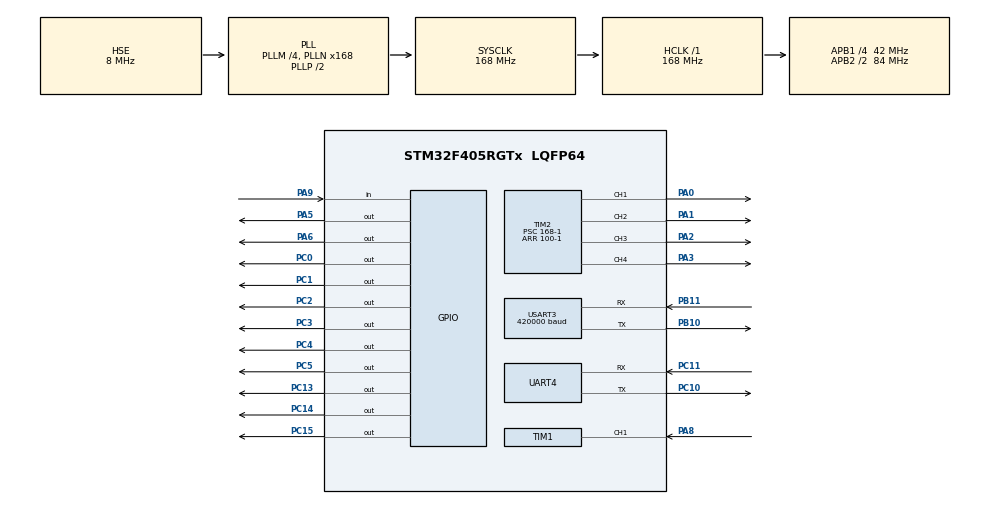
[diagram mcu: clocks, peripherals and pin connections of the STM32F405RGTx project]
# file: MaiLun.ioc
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Mcu.Family=STM32F4
Mcu.Name=STM32F405RGTx
Mcu.Package=LQFP64
NVIC.PriorityGroup=NVIC_PRIORITYGROUP_4
NVIC.TIM1_CC_IRQn=true\:1\:0\:true\:false\:true\:true\:true\:true
NVIC.TIM3_IRQn=true\:2\:0\:true\:false\:true\:true\:true\:true
NVIC.UART4_IRQn=true\:2\:0\:true\:false\:true\:true\:true\:true
NVIC.USART3_IRQn=true\:1\:0\:true\:false\:true\:true\:true\:true
PA0-WKUP.Signal=S_TIM2_CH1_ETR
PA1.Signal=S_TIM2_CH2
PA13.Mode=Serial_Wire
PA13.Signal=SYS_JTMS-SWDIO
PA14.Mode=Serial_Wire
PA14.Signal=SYS_JTCK-SWCLK
PA2.Signal=S_TIM2_CH3
PA3.Signal=S_TIM2_CH4
PA5.Signal=GPIO_Output
PA6.Signal=GPIO_Output
PA8.Signal=S_TIM1_CH1
PA9.Signal=GPIO_Input
PB10.Mode=Asynchronous
PB10.Signal=USART3_TX
PB11.Mode=Asynchronous
PB11.Signal=USART3_RX
PC0.Signal=GPIO_Output
PC1.Signal=GPIO_Output
PC10.Mode=Asynchronous
PC10.Signal=UART4_TX
PC11.Mode=Asynchronous
PC11.Signal=UART4_RX
PC13-ANTI_TAMP.Signal=GPIO_Output
PC14-OSC32_IN.Signal=GPIO_Output
PC15-OSC32_OUT.Signal=GPIO_Output
PC2.Signal=GPIO_Output
PC3.Signal=GPIO_Output
PC4.Signal=GPIO_Output
PC5.Signal=GPIO_Output
PH0-OSC_IN.Mode=HSE-External-Oscillator
PH0-OSC_IN.Signal=RCC_OSC_IN
PH1-OSC_OUT.Mode=HSE-External-Oscillator
PH1-OSC_OUT.Signal=RCC_OSC_OUT
ProjectManager.HeapSize=0x200
ProjectManager.StackSize=0x400
ProjectManager.TargetToolchain=CMake
RCC.48MHZClocksFreq_Value=84000000
RCC.AHBFreq_Value=168000000
RCC.APB1CLKDivider=RCC_HCLK_DIV4
RCC.APB1Freq_Value=42000000
RCC.APB1TimFreq_Value=84000000
RCC.APB2CLKDivider=RCC_HCLK_DIV2
RCC.APB2Freq_Value=84000000
RCC.APB2TimFreq_Value=168000000
RCC.CortexFreq_Value=168000000
RCC.HCLKFreq_Value=168000000
RCC.HSE_VALUE=8000000
RCC.HSI_VALUE=16000000
RCC.LSE_VALUE=32768
RCC.PLLM=4
RCC.PLLN=168
RCC.PLLSourceVirtual=RCC_PLLSOURCE_HSE
RCC.SYSCLKFreq_VALUE=168000000
RCC.SYSCLKSource=RCC_SYSCLKSOURCE_PLLCLK
RCC.VCOOutputFreq_Value=336000000
SH.S_TIM1_CH1.0=TIM1_CH1,Input_Capture1_from_TI1
SH.S_TIM2_CH1_ETR.0=TIM2_CH1,PWM Generation1 CH1
SH.S_TIM2_CH2.0=TIM2_CH2,PWM Generation2 CH2
SH.S_TIM2_CH3.0=TIM2_CH3,PWM Generation3 CH3
SH.S_TIM2_CH4.0=TIM2_CH4,PWM Generation4 CH4
TIM1.Channel-Input_Capture1_from_TI1=TIM_CHANNEL_1
TIM1.Prescaler=8400-1
TIM2.AutoReloadPreload=TIM_AUTORELOAD_PRELOAD_ENABLE
TIM2.Channel-PWM\ Generation1\ CH1=TIM_CHANNEL_1
TIM2.Channel-PWM\ Generation2\ CH2=TIM_CHANNEL_2
TIM2.Channel-PWM\ Generation3\ CH3=TIM_CHANNEL_3
TIM2.Channel-PWM\ Generation4\ CH4=TIM_CHANNEL_4
TIM2.Period=100-1
TIM2.Prescaler=168-1
TIM3.Period=1000-1
TIM3.Prescaler=8400-1
UART4.VirtualMode=Asynchronous
USART3.BaudRate=420000
USART3.VirtualMode=VM_ASYNC
VP_TIM1_VS_ClockSourceINT.Mode=Internal
VP_TIM2_VS_ClockSourceINT.Mode=Internal
VP_TIM3_VS_ClockSourceINT.Mode=Internal
board=custom

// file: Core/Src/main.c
/* USER CODE BEGIN Header */
/**
  ******************************************************************************
  * @file           : main.c
  * @brief          : Main program body
  ******************************************************************************
  * @attention
  *
  * Copyright (c) 2026 STMicroelectronics.
  * All rights reserved.
  *
  * This software is licensed under terms that can be found in the LICENSE file
  * in the root directory of this software component.
  * If no LICENSE file comes with this software, it is provided AS-IS.
  *
  ******************************************************************************
  */
/* USER CODE END Header */
#include "main.h"
#include "tim.h"
#include "usart.h"
#include "gpio.h"

/* USER CODE BEGIN Includes */

#include "Motor.h"
#include "chassis.h"
#include "elrs.h"
#include "Encoder.h"

/* USER CODE END Includes */

/* USER CODE BEGIN PV */

int8_t ctrl_enable;
int8_t RX = 0;

uint8_t rx_flag = 0; // 接收标志，1表示接收到新数据

/* USER CODE END PV */

void SystemClock_Config(void);

int main(void)
{

  /* MCU Configuration--------------------------------------------------------*/

  /* Reset of all peripherals, Initializes the Flash interface and the Systick. */
  HAL_Init();

  /* Configure the system clock */
  SystemClock_Config();

  /* Initialize all configured peripherals */
  MX_GPIO_Init();
  MX_TIM1_Init();
  MX_USART3_UART_Init();
  MX_TIM2_Init();
  MX_TIM3_Init();
  MX_UART4_Init();
  /* USER CODE BEGIN 2 */
  ELRS_Init();

  // 启动中断
  HAL_TIM_IC_Start_IT(&htim1, TIM_CHANNEL_1);  // 启动单脉冲捕获中断
  HAL_TIM_Base_Start_IT(&htim3);               // 启动100ms定时中断
  /* USER CODE END 2 */

  /* Infinite loop */
  /* USER CODE BEGIN WHILE */
  while (1)
  {

    //TIM4已经关闭

    if (ch5_map == 1792) ctrl_enable = 1;

    Chassis_Task(ctrl_enable,ch3_map, ch4_map ,ch1_map);

    Encoder_Report();

    /* USER CODE END WHILE */

  }
}

void SystemClock_Config(void)
{
  RCC_OscInitTypeDef RCC_OscInitStruct = {0};
  RCC_ClkInitTypeDef RCC_ClkInitStruct = {0};

  /** Configure the main internal regulator output voltage
  */
  __HAL_RCC_PWR_CLK_ENABLE();
  __HAL_PWR_VOLTAGESCALING_CONFIG(PWR_REGULATOR_VOLTAGE_SCALE1);

  /** Initializes the RCC Oscillators according to the specified parameters
  * in the RCC_OscInitTypeDef structure.
  */
  RCC_OscInitStruct.OscillatorType = RCC_OSCILLATORTYPE_HSE;
  RCC_OscInitStruct.HSEState = RCC_HSE_ON;
  RCC_OscInitStruct.PLL.PLLState = RCC_PLL_ON;
  RCC_OscInitStruct.PLL.PLLSource = RCC_PLLSOURCE_HSE;
  RCC_OscInitStruct.PLL.PLLM = 4;
  RCC_OscInitStruct.PLL.PLLN = 168;
  RCC_OscInitStruct.PLL.PLLP = RCC_PLLP_DIV2;
  RCC_OscInitStruct.PLL.PLLQ = 4;
  if (HAL_RCC_OscConfig(&RCC_OscInitStruct) != HAL_OK)
  {
    Error_Handler();
  }

  /** Initializes the CPU, AHB and APB buses clocks
  */
  RCC_ClkInitStruct.ClockType = RCC_CLOCKTYPE_HCLK|RCC_CLOCKTYPE_SYSCLK
                              |RCC_CLOCKTYPE_PCLK1|RCC_CLOCKTYPE_PCLK2;
  RCC_ClkInitStruct.SYSCLKSource = RCC_SYSCLKSOURCE_PLLCLK;
  RCC_ClkInitStruct.AHBCLKDivider = RCC_SYSCLK_DIV1;
  RCC_ClkInitStruct.APB1CLKDivider = RCC_HCLK_DIV4;
  RCC_ClkInitStruct.APB2CLKDivider = RCC_HCLK_DIV2;

  if (HAL_RCC_ClockConfig(&RCC_ClkInitStruct, FLASH_LATENCY_5) != HAL_OK)
  {
    Error_Handler();
  }
}

void Error_Handler(void)
{
  __disable_irq();
  while (1)
  {
  }
}
